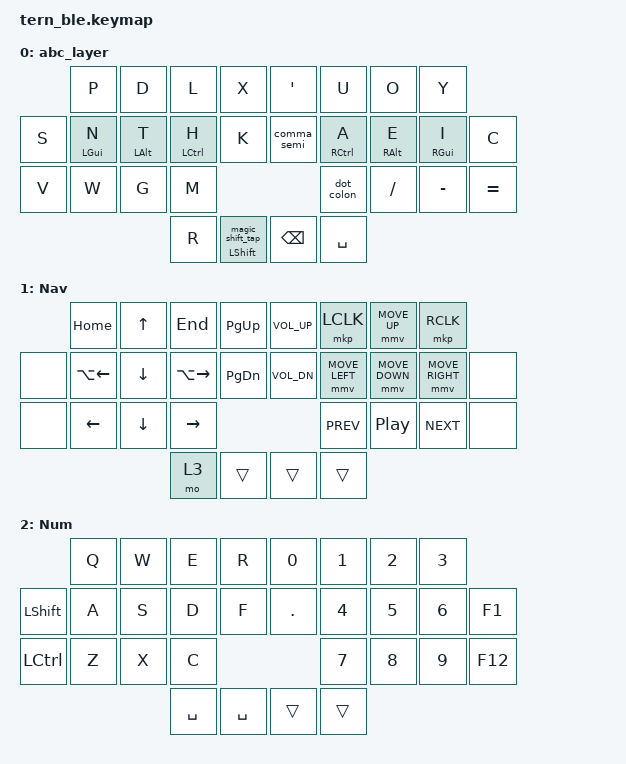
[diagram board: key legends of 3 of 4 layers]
/*
 * Copyright (c) 2022 The ZMK Contributors
 *
 * SPDX-License-Identifier: MIT
 */

#include <behaviors.dtsi>
#include <dt-bindings/zmk/keys.h>
#include <dt-bindings/zmk/bt.h>

#define ZMK_POINTING_DEFAULT_MOVE_VAL 1500  // default: 600
#define ZMK_POINTING_DEFAULT_SCRL_VAL 20    // default: 10

#include <dt-bindings/zmk/pointing.h>

#define ABC_LAYER 0
#define NAV_LAYER 1
#define NUM_LAYER 2

/*       30 KEY MATRIX / LAYOUT MAPPING

      ╭────────────────┬────────────────╮
  ╭───╯  0   1   2   3 │  4   5   6   7 ╰───╮
  │  8   9  10  11  12 │ 13  14  15  16  17 │
  │ 18  19  20  21 ────┼──── 22  23  24  25 │
  ╰───────────╮ 26  27 │ 28  29 ╭───────────╯
              ╰────────┴────────╯             */

#define KEYS_L   0  1  2  3  8  9 10 11 12 18 19 20 21  // Left-hand keys.
#define KEYS_R   4  5  6  7 13 14 15 16 17 22 23 24 25  // Right-hand keys.
#define THUMBS  26 27 28 29                             // Thumb keys.
#define MAGIC_SHIFT &magic_shift LSHFT 0

// Continuation list for caps word
&caps_word { continue-list = <UNDERSCORE MINUS>; };

/ {
    behaviors {
        hml: home_row_mod_left {
            compatible = "zmk,behavior-hold-tap";
            #binding-cells = <2>;
            flavor = "balanced";
            require-prior-idle-ms = <150>;
            tapping-term-ms = <280>;
            quick-tap-ms = <175>;
            bindings = <&kp>, <&kp>;
            hold-trigger-key-positions = <KEYS_R THUMBS>;
            hold-trigger-on-release;
        };
        hmr: home_row_mod_right {
            compatible = "zmk,behavior-hold-tap";
            #binding-cells = <2>;
            flavor = "balanced";
            require-prior-idle-ms = <150>;
            tapping-term-ms = <280>;
            quick-tap-ms = <175>;
            bindings = <&kp>, <&kp>;
            hold-trigger-key-positions = <KEYS_L THUMBS>;
            hold-trigger-on-release;
        };
        magic_shift: magic_shift {
            compatible = "zmk,behavior-hold-tap";
            #binding-cells = <2>;
            flavor = "balanced";
            tapping-term-ms = <200>;
            quick-tap-ms = <175>;
            bindings = <&kp>, <&magic_shift_tap>;
        };
        magic_shift_tap: magic_shift_tap {
            compatible = "zmk,behavior-mod-morph";
            #binding-cells = <0>;
            bindings = <&sk LSHFT>, <&caps_word>;
            mods = <(MOD_LSFT|MOD_RSFT)>;
        };
        dot_colon: dot_colon {
            compatible = "zmk,behavior-mod-morph";
            #binding-cells = <0>;
            bindings = <&kp DOT>, <&kp COLON>;
            mods = <(MOD_LSFT|MOD_RSFT)>;
        };
        comma_semi: comma_semi {
            compatible = "zmk,behavior-mod-morph";
            #binding-cells = <0>;
            bindings = <&kp COMMA>, <&kp SEMI>;
            mods = <(MOD_LSFT|MOD_RSFT)>;
        };
        lpar_lt: lpar_lt {
            compatible = "zmk,behavior-mod-morph";
            #binding-cells = <0>;
            bindings = <&kp LPAR>, <&kp LT>;
            mods = <(MOD_LSFT|MOD_RSFT)>;
        };
        rpar_gt: rpar_gt {
            compatible = "zmk,behavior-mod-morph";
            #binding-cells = <0>;
            bindings = <&kp RPAR>, <&kp GT>;
            mods = <(MOD_LSFT|MOD_RSFT)>;
        };
    };

    combos {
        compatible = "zmk,combos";

// ---------------------------------------------
//      ABC_LAYER + NAV_LAYER + NUM_LAYER
// ---------------------------------------------

        combo_boot {                    //      ╭────────────────┬────────────────╮
            timeout-ms = <50>;          //  ╭───╯  0   1   2   ● │  ●   5   6   7 ╰───╮
            key-positions = <3 4>;      //  │  8   9  10  11  12 │ 13  14  15  16  17 │
            bindings = <&bootloader>;   //  │ 18  19  20  21 ────┼──── 22  23  24  25 │
        };                              //  ╰───────────╮ 26  27 │ 28  29 ╭───────────╯

        combo_reset {                   //      ╭────────────────┬────────────────╮
            timeout-ms = <50>;          //  ╭───╯  0   1   2   3 │  4   5   6   7 ╰───╮
            key-positions = <12 13>;    //  │  8   9  10  11   ● │  ●  14  15  16  17 │
            bindings = <&sys_reset>;    //  │ 18  19  20  21 ────┼──── 22  23  24  25 │
        };                              //  ╰───────────╮ 26  27 │ 28  29 ╭───────────╯

        combo_del {                     //      ╭────────────────┬────────────────╮
            timeout-ms = <50>;          //  ╭───╯  0   1   2   3 │  4   5   6   7 ╰───╮
            key-positions = <27 28>;    //  │  8   9  10  11  12 │ 13  14  15  16  17 │
            bindings = <&kp DEL>;       //  │ 18  19  20  21 ────┼──── 22  23  24  25 │
        };                              //  ╰───────────╮ 26   ● │  ●  29 ╭───────────╯

        combo_esc {                     //      ╭────────────────┬────────────────╮
            timeout-ms = <50>;          //  ╭───╯  0   1   2   3 │  4   5   6   7 ╰───╮
            key-positions = <26 27>;    //  │  8   9  10  11  12 │ 13  14  15  16  17 │
            bindings = <&kp ESC>;       //  │ 18  19  20  21 ────┼──── 22  23  24  25 │
        };                              //  ╰───────────╮  ●   ● │ 28  29 ╭───────────╯

        combo_return {                  //      ╭────────────────┬────────────────╮
            timeout-ms = <50>;          //  ╭───╯  0   1   2   3 │  4   5   6   7 ╰───╮
            key-positions = <28 29>;    //  │  8   9  10  11  12 │ 13  14  15  16  17 │
            bindings = <&kp RET>;       //  │ 18  19  20  21 ────┼──── 22  23  24  25 │
        };                              //  ╰───────────╮ 26  27 │  ●   ● ╭───────────╯

        combo_tab {                     //      ╭────────────────┬────────────────╮
            timeout-ms = <50>;          //  ╭───╯  0   1   2   3 │  4   5   6   7 ╰───╮
            key-positions = <8 9>;      //  │  ●   ●  10  11  12 │ 13  14  15  16  17 │
            bindings = <&kp TAB>;       //  │ 18  19  20  21 ────┼──── 22  23  24  25 │
        };                              //  ╰───────────╮ 26  27 │ 28  29 ╭───────────╯

        combo_copy {                    //      ╭────────────────┬────────────────╮
            timeout-ms = <50>;          //  ╭───╯  0   1   2   3 │  4   5   6   7 ╰───╮
            key-positions = <19 20>;    //  │  8   9  10  11  12 │ 13  14  15  16  17 │
            bindings = <&kp LC(C)>;     //  │ 18   ●   ●  21 ────┼──── 22  23  24  25 │
        };                              //  ╰───────────╮ 26  27 │ 28  29 ╭───────────╯

        combo_cut {                     //      ╭────────────────┬────────────────╮
            timeout-ms = <50>;          //  ╭───╯  0   1   2   3 │  4   5   6   7 ╰───╮
            key-positions = <19 21>;    //  │  8   9  10  11  12 │ 13  14  15  16  17 │
            bindings = <&kp LC(X)>;     //  │ 18   ●  20   ● ────┼──── 22  23  24  25 │
        };                              //  ╰───────────╮ 26  27 │ 28  29 ╭───────────╯

        combo_paste {                   //      ╭────────────────┬────────────────╮
            timeout-ms = <50>;          //  ╭───╯  0   1   2   3 │  4   5   6   7 ╰───╮
            key-positions = <20 21>;    //  │  8   9  10  11  12 │ 13  14  15  16  17 │
            bindings = <&kp LC(V)>;     //  │ 18  19   ●   ● ────┼──── 22  23  24  25 │
        };                              //  ╰───────────╮ 26  27 │ 28  29 ╭───────────╯

// ---------------------------------------------
//                  BLUETOOTH
// ---------------------------------------------

        combo_bt_sel0 {                 //      ╭────────────────┬────────────────╮
            timeout-ms = <50>;          //  ╭───╯  0   1   ●   3 │  4   ●   6   7 ╰───╮
            key-positions = <2 5>;      //  │  8   9  10  11  12 │ 13  14  15  16  17 │
            bindings = <&bt BT_SEL 0>;  //  │ 18  19  20  21 ────┼──── 22  23  24  25 │
        };                              //  ╰───────────╮ 26  27 │ 28  29 ╭───────────╯

        combo_bt_sel1 {                 //      ╭────────────────┬────────────────╮
            timeout-ms = <50>;          //  ╭───╯  0   ●   2   3 │  4   5   ●   7 ╰───╮
            key-positions = <1 6>;      //  │  8   9  10  11  12 │ 13  14  15  16  17 │
            bindings = <&bt BT_SEL 1>;  //  │ 18  19  20  21 ────┼──── 22  23  24  25 │
        };                              //  ╰───────────╮ 26  27 │ 28  29 ╭───────────╯

        combo_bt_sel2 {                 //      ╭────────────────┬────────────────╮
            timeout-ms = <50>;          //  ╭───╯  ●   1   2   3 │  4   5   6   ● ╰───╮
            key-positions = <0 7>;      //  │  8   9  10  11  12 │ 13  14  15  16  17 │
            bindings = <&bt BT_SEL 2>;  //  │ 18  19  20  21 ────┼──── 22  23  24  25 │
        };                              //  ╰───────────╮ 26  27 │ 28  29 ╭───────────╯

        combo_bt_clr {                  //      ╭────────────────┬────────────────╮
            timeout-ms = <50>;          //  ╭───╯  0   1   2   ● │  ●   5   6   7 ╰───╮
            key-positions = <3 4 12 13>;//  │  8   9  10  11   ● │  ●  14  15  16  17 │
            bindings = <&bt BT_CLR>;    //  │ 18  19  20  21 ────┼──── 22  23  24  25 │
        };                              //  ╰───────────╮ 26  27 │ 28  29 ╭───────────╯

// ---------------------------------------------
//                  ABC_LAYER
// ---------------------------------------------

        combo_f {                       //      ╭────────────────┬────────────────╮
            timeout-ms = <50>;          //  ╭───╯  ●   ●   2   3 │  4   5   6   7 ╰───╮
            key-positions = <0 1>;      //  │  8   9  10  11  12 │ 13  14  15  16  17 │
            bindings = <&kp F>;         //  │ 18  19  20  21 ────┼──── 22  23  24  25 │
            layers = <0>;               //  ╰───────────╮ 26  27 │ 28  29 ╭───────────╯
        };                              //              ╰────────┴────────╯

        combo_j {                       //      ╭────────────────┬────────────────╮
            timeout-ms = <50>;          //  ╭───╯  0   1   2   ● │  4   5   6   7 ╰───╮
            key-positions = <3 12>;     //  │  8   9  10  11   ● │ 13  14  15  16  17 │
            bindings = <&kp J>;         //  │ 18  19  20  21 ────┼──── 22  23  24  25 │
            layers = <0>;               //  ╰───────────╮ 26  27 │ 28  29 ╭───────────╯
        };                              //              ╰────────┴────────╯

        combo_b {                       //      ╭────────────────┬────────────────╮
            timeout-ms = <50>;          //  ╭───╯  0   1   2   3 │  4   5   ●   ● ╰───╮
            key-positions = <6 7>;      //  │  8   9  10  11  12 │ 13  14  15  16  17 │
            bindings = <&kp B>;         //  │ 18  19  20  21 ────┼──── 22  23  24  25 │
            layers = <0>;               //  ╰───────────╮ 26  27 │ 28  29 ╭───────────╯
        };                              //              ╰────────┴────────╯

        combo_z {                       //      ╭────────────────┬────────────────╮
            timeout-ms = <50>;          //  ╭───╯  0   1   2   3 │  4   5   6   7 ╰───╮
            key-positions = <16 17>;    //  │  8   9  10  11  12 │ 13  14  15   ●   ● │
            bindings = <&kp Z>;         //  │ 18  19  20  21 ────┼──── 22  23  24  25 │
            layers = <0>;               //  ╰───────────╮ 26  27 │ 28  29 ╭───────────╯
        };                              //              ╰────────┴────────╯

        combo_q {                       //      ╭────────────────┬────────────────╮
            timeout-ms = <50>;          //  ╭───╯  0   1   2   3 │  4   5   6   7 ╰───╮
            key-positions = <24 25>;    //  │  8   9  10  11  12 │ 13  14  15  16  17 │
            bindings = <&kp Q>;         //  │ 18  19  20  21 ────┼──── 22  23   ●   ● │
            layers = <0>;               //  ╰───────────╮ 26  27 │ 28  29 ╭───────────╯
        };                              //              ╰────────┴────────╯

        combo_grave {                   //      ╭────────────────┬────────────────╮
            timeout-ms = <50>;          //  ╭───╯  0   1   2   3 │  4   5   6   7 ╰───╮
            key-positions = <20 26>;    //  │  8   9  10  11  12 │ 13  14  15  16  17 │
            bindings = <&kp GRAVE>;     //  │ 18  19   ●  21 ────┼──── 22  23  24  25 │
            layers = <0>;               //  ╰───────────╮  ●  27 │ 28  29 ╭───────────╯
        };                              //              ╰────────┴────────╯

        combo_tilde {                   //      ╭────────────────┬────────────────╮
            timeout-ms = <50>;          //  ╭───╯  0   1   2   3 │  4   5   6   7 ╰───╮
            key-positions = <10 16>;    //  │  8   9   ●  11  12 │ 13  14  15   ●  17 │
            bindings = <&kp TILDE>;     //  │ 18  19  20  21 ────┼──── 22  23  24  25 │
            layers = <0>;               //  ╰───────────╮ 26  27 │ 28  29 ╭───────────╯
        };                              //              ╰────────┴────────╯

        combo_excl {                    //      ╭────────────────┬────────────────╮
            timeout-ms = <50>;          //  ╭───╯  0   1   2   3 │  ●   5   6   7 ╰───╮
            key-positions = <4 13>;     //  │  8   9  10  11  12 │  ●  14  15  16  17 │
            bindings = <&kp EXCL>;      //  │ 18  19  20  21 ────┼──── 22  23  24  25 │
            layers = <0>;               //  ╰───────────╮ 26  27 │ 28  29 ╭───────────╯
        };                              //              ╰────────┴────────╯

        combo_arroba {                  //      ╭────────────────┬────────────────╮
            timeout-ms = <50>;          //  ╭───╯  0   1   2   3 │  4   5   6   7 ╰───╮
            key-positions = <10 14>;    //  │  8   9   ●  11  12 │ 13   ●  15  16  17 │
            bindings = <&kp AT>;        //  │ 18  19  20  21 ────┼──── 22  23  24  25 │
            layers = <0>;               //  ╰───────────╮ 26  27 │ 28  29 ╭───────────╯
        };                              //              ╰────────┴────────╯

        combo_hash {                    //      ╭────────────────┬────────────────╮
            timeout-ms = <50>;          //  ╭───╯  0   1   2   3 │  4   5   6   7 ╰───╮
            key-positions = <11 14>;    //  │  8   9  10   ●  12 │ 13   ●  15  16  17 │
            bindings = <&kp HASH>;      //  │ 18  19  20  21 ────┼──── 22  23  24  25 │
            layers = <0>;               //  ╰───────────╮ 26  27 │ 28  29 ╭───────────╯
        };                              //              ╰────────┴────────╯

        combo_dollar {                  //      ╭────────────────┬────────────────╮
            timeout-ms = <50>;          //  ╭───╯  0   1   2   3 │  4   5   6   7 ╰───╮
            key-positions = <8 16>;     //  │  ●   9  10  11  12 │ 13  14  15   ●  17 │
            bindings = <&kp DLLR>;      //  │ 18  19  20  21 ────┼──── 22  23  24  25 │
            layers = <0>;               //  ╰───────────╮ 26  27 │ 28  29 ╭───────────╯
        };                              //              ╰────────┴────────╯

        combo_procent {                 //      ╭────────────────┬────────────────╮
            timeout-ms = <50>;          //  ╭───╯  ●   1   2   3 │  4   5   6   7 ╰───╮
            key-positions = <0 26>;     //  │  8   9  10  11  12 │ 13  14  15  16  17 │
            bindings = <&kp PRCNT>;     //  │ 18  19  20  21 ────┼──── 22  23  24  25 │
            layers = <0>;               //  ╰───────────╮  ●  27 │ 28  29 ╭───────────╯
        };                              //              ╰────────┴────────╯

        combo_carret {                  //      ╭────────────────┬────────────────╮
            timeout-ms = <50>;          //  ╭───╯  0   1   2   3 │  4   5   6   7 ╰───╮
            key-positions = <14 17>;    //  │  8   9  10  11  12 │ 13   ●  15  16   ● │
            bindings = <&kp CARET>;     //  │ 18  19  20  21 ────┼──── 22  23  24  25 │
            layers = <0>;               //  ╰───────────╮ 26  27 │ 28  29 ╭───────────╯
        };                              //              ╰────────┴────────╯

        combo_amps {                    //      ╭────────────────┬────────────────╮
            timeout-ms = <50>;          //  ╭───╯  0   1   2   3 │  4   5   6   7 ╰───╮
            key-positions = <14 21>;    //  │  8   9  10  11  12 │ 13   ●  15  16  17 │
            bindings = <&kp AMPS>;      //  │ 18  19  20   ● ────┼──── 22  23  24  25 │
            layers = <0>;               //  ╰───────────╮ 26  27 │ 28  29 ╭───────────╯
        };                              //              ╰────────┴────────╯

        combo_asterisk {                //      ╭────────────────┬────────────────╮
            timeout-ms = <50>;          //  ╭───╯  0   1   2   3 │  4   5   6   7 ╰───╮
            key-positions = <8 10>;     //  │  ●   9   ●  11  12 │ 13  14  15  16  17 │
            bindings = <&kp ASTERISK>;  //  │ 18  19  20  21 ────┼──── 22  23  24  25 │
            layers = <0>;               //  ╰───────────╮ 26  27 │ 28  29 ╭───────────╯
        };                              //              ╰────────┴────────╯

        combo_bslh {                    //      ╭────────────────┬────────────────╮
            timeout-ms = <50>;          //  ╭───╯  0   1   2   3 │  4   5   ●   ● ╰───╮
            key-positions = <6 7 8>;    //  │  ●   9  10  11  12 │ 13  14  15  16  17 │
            bindings = <&kp BSLH>;      //  │ 18  19  20  21 ────┼──── 22  23  24  25 │
            layers = <0>;               //  ╰───────────╮ 26  27 │ 28  29 ╭───────────╯
        };                              //              ╰────────┴────────╯

        combo_pipe {                    //      ╭────────────────┬────────────────╮
            timeout-ms = <50>;          //  ╭───╯  ●   1   2   3 │  4   5   6   7 ╰───╮
            key-positions = <0 16>;     //  │  8   9  10  11  12 │ 13  14  15   ●  17 │
            bindings = <&kp PIPE>;      //  │ 18  19  20  21 ────┼──── 22  23  24  25 │
            layers = <0>;               //  ╰───────────╮ 26  27 │ 28  29 ╭───────────╯
        };                              //              ╰────────┴────────╯

        combo_lpl {                     //      ╭────────────────┬────────────────╮
            timeout-ms = <50>;          //  ╭───╯  0   1   2   3 │  4   5   6   7 ╰───╮
            key-positions = <14 15>;    //  │  8   9  10  11  12 │ 13   ●   ●  16  17 │
            bindings = <&lpar_lt>;      //  │ 18  19  20  21 ────┼──── 22  23  24  25 │
            layers = <0>;               //  ╰───────────╮ 26  27 │ 28  29 ╭───────────╯
        };                              //              ╰────────┴────────╯

        combo_rpg {                     //      ╭────────────────┬────────────────╮
            timeout-ms = <50>;          //  ╭───╯  0   1   2   3 │  4   5   6   7 ╰───╮
            key-positions = <15 16>;    //  │  8   9  10  11  12 │ 13  14   ●   ●  17 │
            bindings = <&rpar_gt>;      //  │ 18  19  20  21 ────┼──── 22  23  24  25 │
            layers = <0>;               //  ╰───────────╮ 26  27 │ 28  29 ╭───────────╯
        };                              //              ╰────────┴────────╯

        combo_lbkt {                    //      ╭────────────────┬────────────────╮
            timeout-ms = <50>;          //  ╭───╯  0   1   2   3 │  4   5   6   7 ╰───╮
            key-positions = <22 23>;    //  │  8   9  10  11  12 │ 13  14  15  16  17 │
            bindings = <&kp LBKT>;      //  │ 18  19  20  21 ────┼────  ●   ●  24  25 │
            layers = <0>;               //  ╰───────────╮ 26  27 │ 28  29 ╭───────────╯
        };                              //              ╰────────┴────────╯

        combo_rbkt {                    //      ╭────────────────┬────────────────╮
            timeout-ms = <50>;          //  ╭───╯  0   1   2   3 │  4   5   6   7 ╰───╮
            key-positions = <23 24>;    //  │  8   9  10  11  12 │ 13  14  15  16  17 │
            bindings = <&kp RBKT>;      //  │ 18  19  20  21 ────┼──── 22   ●   ●  25 │
            layers = <0>;               //  ╰───────────╮ 26  27 │ 28  29 ╭───────────╯
        };                              //              ╰────────┴────────╯

        combo_show_desktop {            //      ╭────────────────┬────────────────╮
            timeout-ms = <50>;          //  ╭───╯  0   ●   2   3 │  4   5   6   7 ╰───╮
            key-positions = <1 10>;     //  │  8   9   ●  11  12 │ 13  14  15  16  17 │
            bindings = <&kp F11>;       //  │ 18  19  20  21 ────┼──── 22  23  24  25 │
            layers = <0>;               //  ╰───────────╮ 26  27 │ 28  29 ╭───────────╯
        };                              //              ╰────────┴────────╯

        combo_sleep {                   //      ╭────────────────┬────────────────╮
            timeout-ms = <50>;          //  ╭───╯  0   1   ●   3 │  4   5   6   7 ╰───╮
            key-positions = <2 8 15>;   //  │  ●   9  10  11  12 │ 13  14   ●  16  17 │
            bindings = <&kp K_SLEEP>;   //  │ 18  19  20  21 ────┼──── 22  23  24  25 │
            layers = <0>;               //  ╰───────────╮ 26  27 │ 28  29 ╭───────────╯
        };                              //              ╰────────┴────────╯

        combo_launch_app {              //      ╭────────────────┬────────────────╮
            timeout-ms = <50>;          //  ╭───╯  ●   1   ●   3 │  4   5   6   7 ╰───╮
            key-positions = <0 2>;      //  │  8   9  10  11  12 │ 13  14  15  16  17 │
            bindings = <&kp LGUI>;      //  │ 18  19  20  21 ────┼──── 22  23  24  25 │
            layers = <0>;               //  ╰───────────╮ 26  27 │ 28  29 ╭───────────╯
        };                              //              ╰────────┴────────╯

        combo_screenshot {              //      ╭────────────────┬────────────────╮
            timeout-ms = <50>;          //  ╭───╯  ●   1   2   3 │  4   5   6   7 ╰───╮
            key-positions = <0 8>;      //  │  ●   9  10  11  12 │ 13  14  15  16  17 │
            bindings = <&kp LS(LG(PSCRN))>;
	                                //  │ 18  19  20  21 ────┼──── 22  23  24  25 │
            layers = <0>;               //  ╰───────────╮ 26  27 │ 28  29 ╭───────────╯
        };                              //              ╰────────┴────────╯

        combo_screen_record {           //      ╭────────────────┬────────────────╮
            timeout-ms = <50>;          //  ╭───╯  0   1   2   3 │  4   5   6   7 ╰───╮
            key-positions = <8 26>;     //  │  ●   9  10  11  12 │ 13  14  15  16  17 │
            bindings = <&kp LS(LG(R))>; //  │ 18  19  20  21 ────┼──── 22  23  24  25 │
            layers = <0>;               //  ╰───────────╮  ●  27 │ 28  29 ╭───────────╯
        };                              //              ╰────────┴────────╯

        combo_menu {                    //      ╭────────────────┬────────────────╮
            timeout-ms = <50>;          //  ╭───╯  0   1   2   3 │  4   5   6   7 ╰───╮
            key-positions = <11 15>;    //  │  8   9  10  11  12 │ 13  14   ●  16  17 │
            bindings = <&kp K_MENU>;    //  │ 18  19  20   ● ────┼──── 22  23  24  25 │
            layers = <0>;               //  ╰───────────╮ 26  27 │ 28  29 ╭───────────╯
        };                              //              ╰────────┴────────╯

// ---------------------------------------------
//             ABC_LAYER + NAV_LAYER
// ---------------------------------------------

        combo_to_num {                  //      ╭────────────────┬────────────────╮
            timeout-ms = <50>;          //  ╭───╯  0   ●   ●   3 │  4   5   6   7 ╰───╮
            key-positions = <1 2>;      //  │  8   9  10  11  12 │ 13  14  15  16  17 │
            bindings = <&to NUM_LAYER>; //  │ 18  19  20  21 ────┼──── 22  23  24  25 │
            layers = <0 1>;             //  ╰───────────╮ 26  27 │ 28  29 ╭───────────╯
        };                              //              ╰────────┴────────╯

// ---------------------------------------------
//                   NAV_LAYER
// ---------------------------------------------

        combo_tog_nav {                 //      ╭────────────────┬────────────────╮
            timeout-ms = <50>;          //  ╭───╯  0   1   2   3 │  4   ●   ●   7 ╰───╮
            key-positions = <5 6>;      //  │  8   9  10  11  12 │ 13  14  15  16  17 │
            bindings = <&tog NAV_LAYER>;//  │ 18  19  20  21 ────┼──── 22  23  24  25 │
            layers = <1>;               //  ╰───────────╮ 26  27 │ 28  29 ╭───────────╯
        };                              //              ╰────────┴────────╯

        combo_mute {                    //      ╭────────────────┬────────────────╮
            timeout-ms = <50>;          //  ╭───╯  0   1   2   3 │  ●   5   6   7 ╰───╮
            key-positions = <4 13>;     //  │  8   9  10  11  12 │  ●  14  15  16  17 │
            bindings = <&kp C_MUTE>;    //  │ 18  19  20  21 ────┼──── 22  23  24  25 │
            layers = <1>;               //  ╰───────────╮ 26  27 │ 28  29 ╭───────────╯
        };                              //              ╰────────┴────────╯

// ---------------------------------------------
//             ABC_LAYER + NUM_LAYER
// ---------------------------------------------

        combo_to_nav {                  //      ╭────────────────┬────────────────╮
            timeout-ms = <50>;          //  ╭───╯  0   1   2   3 │  4   ●   ●   7 ╰───╮
            key-positions = <5 6>;      //  │  8   9  10  11  12 │ 13  14  15  16  17 │
            bindings = <&to NAV_LAYER>; //  │ 18  19  20  21 ────┼──── 22  23  24  25 │
            layers = <0 2>;             //  ╰───────────╮ 26  27 │ 28  29 ╭───────────╯
        };                              //              ╰────────┴────────╯

// ---------------------------------------------
//                   NUM_LAYER
// ---------------------------------------------

        combo_tog_num {                 //      ╭────────────────┬────────────────╮
            timeout-ms = <50>;          //  ╭───╯  0   ●   ●   3 │  4   5   6   7 ╰───╮
            key-positions = <1 2>;      //  │  8   9  10  11  12 │ 13  14  15  16  17 │
            bindings = <&tog NUM_LAYER>;//  │ 18  19  20  21 ────┼──── 22  23  24  25 │
            layers = <2>;               //  ╰───────────╮ 26  27 │ 28  29 ╭───────────╯
        };                              //              ╰────────┴────────╯

        combo_g {                       //      ╭────────────────┬────────────────╮
            timeout-ms = <50>;          //  ╭───╯  0   1   2   ● │  4   5   6   7 ╰───╮
            key-positions = <3 12>;     //  │  8   9  10  11   ● │ 13  14  15  16  17 │
            bindings = <&kp G>;         //  │ 18  19  20  21 ────┼──── 22  23  24  25 │
            layers = <2>;               //  ╰───────────╮ 26  27 │ 28  29 ╭───────────╯
        };                              //              ╰────────┴────────╯
    };

    keymap {
        compatible = "zmk,keymap";

        abc_layer {
            bindings = <
            //              ╭─────────────┬─────────────┬─────────────┬─────────────╮ ╭─────────────┬─────────────┬─────────────┬─────────────╮
                              &kp P         &kp D         &kp L         &kp X           &kp SQT       &kp U         &kp O         &kp Y
            //╭─────────────┼─────────────┼─────────────┼─────────────┼─────────────┤ ├─────────────┼─────────────┼─────────────┼─────────────┼─────────────╮
                &kp S         &hml LGUI N   &hml LALT T   &hml LCTRL H  &kp K           &comma_semi   &hmr RCTRL A  &hmr RALT E   &hmr RGUI I   &kp C
            //├─────────────┼─────────────┼─────────────┼─────────────┼─────────────╯ ╰─────────────┼─────────────┼─────────────┼─────────────┼─────────────┤
                &kp V         &kp W         &kp G         &kp M                                       &dot_colon    &kp SLASH     &kp MINUS     &kp EQUAL
            //╰─────────────┴─────────────┴─────────────┼─────────────┼─────────────╮ ╭─────────────┼─────────────┼─────────────┴─────────────┴─────────────╯
                                                          &kp R         MAGIC_SHIFT     &kp BKSP      &kp SPACE
            //                                          ╰─────────────┴─────────────╯ ╰─────────────┴─────────────╯
            >;
        };

        nav_layer {
            display-name = "Nav";
            bindings = <
            //              ╭─────────────┬─────────────┬─────────────┬─────────────╮ ╭─────────────┬─────────────┬─────────────┬─────────────╮
                              &kp HOME      &kp UP        &kp END       &kp PG_UP       &kp C_VOL_UP  &mkp LCLK     &mmv MOVE_UP  &mkp RCLK
            //╭─────────────┼─────────────┼─────────────┼─────────────┼─────────────┤ ├─────────────┼─────────────┼─────────────┼─────────────┼─────────────╮
                &none         &kp LA(LEFT)  &kp DOWN      &kp LA(RIGHT) &kp PG_DN       &kp C_VOL_DN  &mmv MOVE_LEFT &mmv MOVE_DOWN &mmv MOVE_RIGHT &none
            //├─────────────┼─────────────┼─────────────┼─────────────┼─────────────╯ ╰─────────────┼─────────────┼─────────────┼─────────────┼─────────────┤
	        &none         &kp LEFT      &kp DOWN      &kp RIGHT                                   &kp C_PREV    &kp C_PP      &kp C_NEXT    &none
            //╰─────────────┴─────────────┴─────────────┼─────────────┼─────────────╮ ╭─────────────┼─────────────┼─────────────┴─────────────┴─────────────╯
                                                           &mo 3        &trans          &trans        &trans
            //                                          ╰─────────────┴─────────────╯ ╰─────────────┴─────────────╯
            >;
        };

        num_layer {
            display-name = "Num";
            bindings = <
            //              ╭─────────────┬─────────────┬─────────────┬─────────────╮ ╭─────────────┬─────────────┬─────────────┬─────────────╮
                              &kp Q         &kp W         &kp E         &kp R           &kp N0        &kp N1        &kp N2        &kp N3
            //╭─────────────┼─────────────┼─────────────┼─────────────┼─────────────┤ ├─────────────┼─────────────┼─────────────┼─────────────┼─────────────╮
                &kp LSHFT     &kp A         &kp S         &kp D         &kp F           &kp DOT       &kp N4        &kp N5        &kp N6        &kp F1
            //├─────────────┼─────────────┼─────────────┼─────────────┼─────────────╯ ╰─────────────┼─────────────┼─────────────┼─────────────┼─────────────┤
                &kp LCTRL     &kp Z         &kp X         &kp C                                       &kp N7        &kp N8        &kp N9        &kp F12
            //╰─────────────┴─────────────┴─────────────┼─────────────┼─────────────╮ ╭─────────────┼─────────────┼─────────────┴─────────────┴─────────────╯
                                                          &kp SPACE     &kp SPACE       &trans        &trans
            //                                          ╰─────────────┴─────────────╯ ╰─────────────┴─────────────╯
            >;
        };

        nav_layer_2 {
            display-name = "Nav 2";
            bindings = <
            //              ╭─────────────┬─────────────┬─────────────┬─────────────╮ ╭─────────────┬─────────────┬─────────────┬─────────────╮
                              &trans        &trans        &trans        &trans          &trans        &trans        &msc SCRL_DOWN  &trans
            //╭─────────────┼─────────────┼─────────────┼─────────────┼─────────────┤ ├─────────────┼─────────────┼─────────────┼─────────────┼─────────────╮
                &trans        &trans        &trans        &trans        &trans          &trans        &msc SCRL_RIGHT &msc SCRL_UP &msc SCRL_LEFT &trans
            //├─────────────┼─────────────┼─────────────┼─────────────┼─────────────╯ ╰─────────────┼─────────────┼─────────────┼─────────────┼─────────────┤
                &trans        &trans        &trans        &trans        &trans          &trans        &trans        &trans        &trans        &trans
            //╰─────────────┴─────────────┴─────────────┼─────────────┼─────────────╮ ╭─────────────┼─────────────┼─────────────┴─────────────┴─────────────╯
                                                          &trans        &trans          &trans        &trans
            //                                          ╰─────────────┴─────────────╯ ╰─────────────┴─────────────╯
            >;
        };
    };
};
